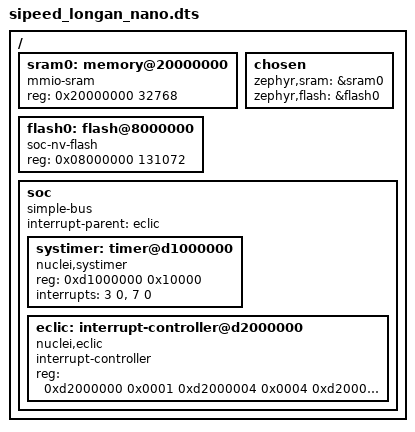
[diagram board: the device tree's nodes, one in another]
/*
 * Copyright (c) 2021 Tokita, Hiroshi <tokita.hiroshi@gmail.com>
 *
 * SPDX-License-Identifier: Apache-2.0
 */
/dts-v1/;

/ {
	#address-cells = <1>;
	#size-cells = <1>;

	sram0: memory@20000000 {
		compatible = "mmio-sram";
		reg = <0x20000000 32768>;
	};

	flash0: flash@8000000 {
		compatible = "soc-nv-flash";
		reg = <0x08000000 131072>;
	};

	chosen {
		zephyr,sram = &sram0;
		zephyr,flash = &flash0;
	};

	soc {
		#address-cells = <1>;
		#size-cells = <1>;
		compatible = "simple-bus";
		interrupt-parent = <&eclic>;
		ranges;

		systimer: timer@d1000000 {
			compatible = "nuclei,systimer";
			reg = <0xd1000000 0x10000>;
			interrupts = <3 0>, <7 0>;
		};

		eclic: interrupt-controller@d2000000 {
			compatible = "nuclei,eclic";
			#address-cells = <0>;
			#interrupt-cells = <2>;
			interrupt-controller;
			reg =  <0xd2000000 0x0001
				0xd2000004 0x0004
				0xd200000b 0x0001
				0xd2001000 0x1000>;
		};
	};
};

